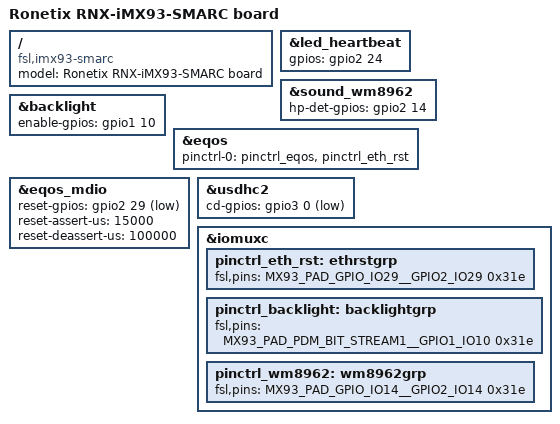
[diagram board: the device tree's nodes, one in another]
// SPDX-License-Identifier: (GPL-2.0+ OR MIT)
/*
 * Copyright 2022 NXP
 * Copyright 2023-2026 Ronetix GmbH
 *
 * Ronetix RNX-iMX93-SMARC, 1GB or 2GB LPDDR4X
 */

/dts-v1/;

#include "imx93-rnx-som.dtsi"

/ {
	model = "Ronetix RNX-iMX93-SMARC board";
	compatible = "fsl,imx93-smarc", "fsl,imx93";
};

&led_heartbeat {
	gpios = <&gpio2 24 GPIO_ACTIVE_HIGH>;
};

&sound_wm8962 {
	hp-det-gpios = <&gpio2 14 GPIO_ACTIVE_HIGH>;
};

&backlight {
	enable-gpios = <&gpio1 10 GPIO_ACTIVE_HIGH>;
};

&eqos {
	pinctrl-0 = <&pinctrl_eqos>, <&pinctrl_eth_rst>;
};

&eqos_mdio {
	/* GPIO2_IO29 resets the EQOS and the FEC PHY */
	reset-gpios = <&gpio2 29 GPIO_ACTIVE_LOW>;
	reset-assert-us = <15000>;
	reset-deassert-us = <100000>;
};

&usdhc2 {
	cd-gpios = <&gpio3 0 GPIO_ACTIVE_LOW>;
};

&iomuxc {
	pinctrl_eth_rst: ethrstgrp {
		fsl,pins = <
			MX93_PAD_GPIO_IO29__GPIO2_IO29		0x31e	/* ETH RST */
		>;
	};

	pinctrl_backlight: backlightgrp {
		fsl,pins = <
			MX93_PAD_PDM_BIT_STREAM1__GPIO1_IO10	0x31e	/* LCD_BL_EN */
		>;
	};

	pinctrl_wm8962: wm8962grp {
		fsl,pins = <
			MX93_PAD_GPIO_IO14__GPIO2_IO14		0x31e	/* Headphone detect */
		>;
	};
};
